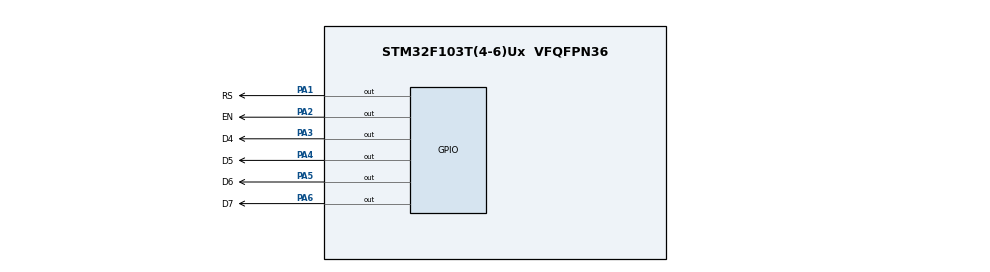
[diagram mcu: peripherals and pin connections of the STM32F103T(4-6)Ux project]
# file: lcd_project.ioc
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Mcu.Family=STM32F1
Mcu.Name=STM32F103T(4-6)Ux
Mcu.Package=VFQFPN36
NVIC.PriorityGroup=NVIC_PRIORITYGROUP_4
PA1.GPIO_Label=RS
PA1.Signal=GPIO_Output
PA2.GPIO_Label=EN
PA2.Signal=GPIO_Output
PA3.GPIO_Label=D4
PA3.Signal=GPIO_Output
PA4.GPIO_Label=D5
PA4.Signal=GPIO_Output
PA5.GPIO_Label=D6
PA5.Signal=GPIO_Output
PA6.GPIO_Label=D7
PA6.Signal=GPIO_Output
ProjectManager.HeapSize=0x200
ProjectManager.StackSize=0x400
ProjectManager.TargetToolchain=STM32CubeIDE
RCC.APB1Freq_Value=8000000
RCC.APB2Freq_Value=8000000
VP_RTC_VS_RTC_Activate.Mode=RTC_Enabled
VP_SYS_VS_ND.Mode=No_Debug
board=custom

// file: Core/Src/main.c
/* USER CODE BEGIN Header */
/**
  ******************************************************************************
  * @file           : main.c
  * @brief          : Main program body
  ******************************************************************************
  * @attention
  *
  * <h2><center>&copy; Copyright (c) 2022 STMicroelectronics.
  * All rights reserved.</center></h2>
  *
  * This software component is licensed by ST under BSD 3-Clause license,
  * the "License"; You may not use this file except in compliance with the
  * License. You may obtain a copy of the License at:
  *                        opensource.org/licenses/BSD-3-Clause
  *
  ******************************************************************************
  */
/* USER CODE END Header */

#include "main.h"

RTC_HandleTypeDef hrtc;

void SystemClock_Config(void);
static void MX_GPIO_Init(void);
static void MX_RTC_Init(void);

int main(void)
{

  /* MCU Configuration--------------------------------------------------------*/

  /* Reset of all peripherals, Initializes the Flash interface and the Systick. */
  HAL_Init();

  /* Configure the system clock */
  SystemClock_Config();

  /* Initialize all configured peripherals */
  MX_GPIO_Init();
  MX_RTC_Init();
  /* USER CODE BEGIN 2 */
  inic_LCD_4bits();
  char frase[32] = "TESTE";
  /* USER CODE END 2 */

  /* Infinite loop */
  while (1)
  {
	  escreve_LCD(frase);
	  HAL_Delay(500);
	  cmd_LCD(0x01);
	  HAL_Delay(500);
  }
}

void SystemClock_Config(void)
{
  RCC_OscInitTypeDef RCC_OscInitStruct = {0};
  RCC_ClkInitTypeDef RCC_ClkInitStruct = {0};
  RCC_PeriphCLKInitTypeDef PeriphClkInit = {0};

  /** Initializes the CPU, AHB and APB busses clocks
  */
  RCC_OscInitStruct.OscillatorType = RCC_OSCILLATORTYPE_HSI|RCC_OSCILLATORTYPE_LSI;
  RCC_OscInitStruct.HSIState = RCC_HSI_ON;
  RCC_OscInitStruct.HSICalibrationValue = RCC_HSICALIBRATION_DEFAULT;
  RCC_OscInitStruct.LSIState = RCC_LSI_ON;
  RCC_OscInitStruct.PLL.PLLState = RCC_PLL_NONE;
  if (HAL_RCC_OscConfig(&RCC_OscInitStruct) != HAL_OK)
  {
    Error_Handler();
  }
  /** Initializes the CPU, AHB and APB busses clocks
  */
  RCC_ClkInitStruct.ClockType = RCC_CLOCKTYPE_HCLK|RCC_CLOCKTYPE_SYSCLK
                              |RCC_CLOCKTYPE_PCLK1|RCC_CLOCKTYPE_PCLK2;
  RCC_ClkInitStruct.SYSCLKSource = RCC_SYSCLKSOURCE_HSI;
  RCC_ClkInitStruct.AHBCLKDivider = RCC_SYSCLK_DIV1;
  RCC_ClkInitStruct.APB1CLKDivider = RCC_HCLK_DIV1;
  RCC_ClkInitStruct.APB2CLKDivider = RCC_HCLK_DIV1;

  if (HAL_RCC_ClockConfig(&RCC_ClkInitStruct, FLASH_LATENCY_0) != HAL_OK)
  {
    Error_Handler();
  }
  PeriphClkInit.PeriphClockSelection = RCC_PERIPHCLK_RTC;
  PeriphClkInit.RTCClockSelection = RCC_RTCCLKSOURCE_LSI;
  if (HAL_RCCEx_PeriphCLKConfig(&PeriphClkInit) != HAL_OK)
  {
    Error_Handler();
  }
}

static void MX_RTC_Init(void)
{

  /** Initialize RTC Only
  */
  hrtc.Instance = RTC;
  hrtc.Init.AsynchPrediv = RTC_AUTO_1_SECOND;
  hrtc.Init.OutPut = RTC_OUTPUTSOURCE_ALARM;
  if (HAL_RTC_Init(&hrtc) != HAL_OK)
  {
    Error_Handler();
  }

}

static void MX_GPIO_Init(void)
{
  GPIO_InitTypeDef GPIO_InitStruct = {0};

  /* GPIO Ports Clock Enable */
  __HAL_RCC_GPIOA_CLK_ENABLE();

  /*Configure GPIO pin Output Level */
  HAL_GPIO_WritePin(GPIOA, RS_Pin|EN_Pin|D4_Pin|D5_Pin
                          |D6_Pin|D7_Pin, GPIO_PIN_RESET);

  /*Configure GPIO pins : RS_Pin EN_Pin D4_Pin D5_Pin
                           D6_Pin D7_Pin */
  GPIO_InitStruct.Pin = RS_Pin|EN_Pin|D4_Pin|D5_Pin
                          |D6_Pin|D7_Pin;
  GPIO_InitStruct.Mode = GPIO_MODE_OUTPUT_PP;
  GPIO_InitStruct.Pull = GPIO_NOPULL;
  GPIO_InitStruct.Speed = GPIO_SPEED_FREQ_LOW;
  HAL_GPIO_Init(GPIOA, &GPIO_InitStruct);

}

void Error_Handler(void)
{
}

/************************ (C) COPYRIGHT STMicroelectronics *****END OF FILE****/
